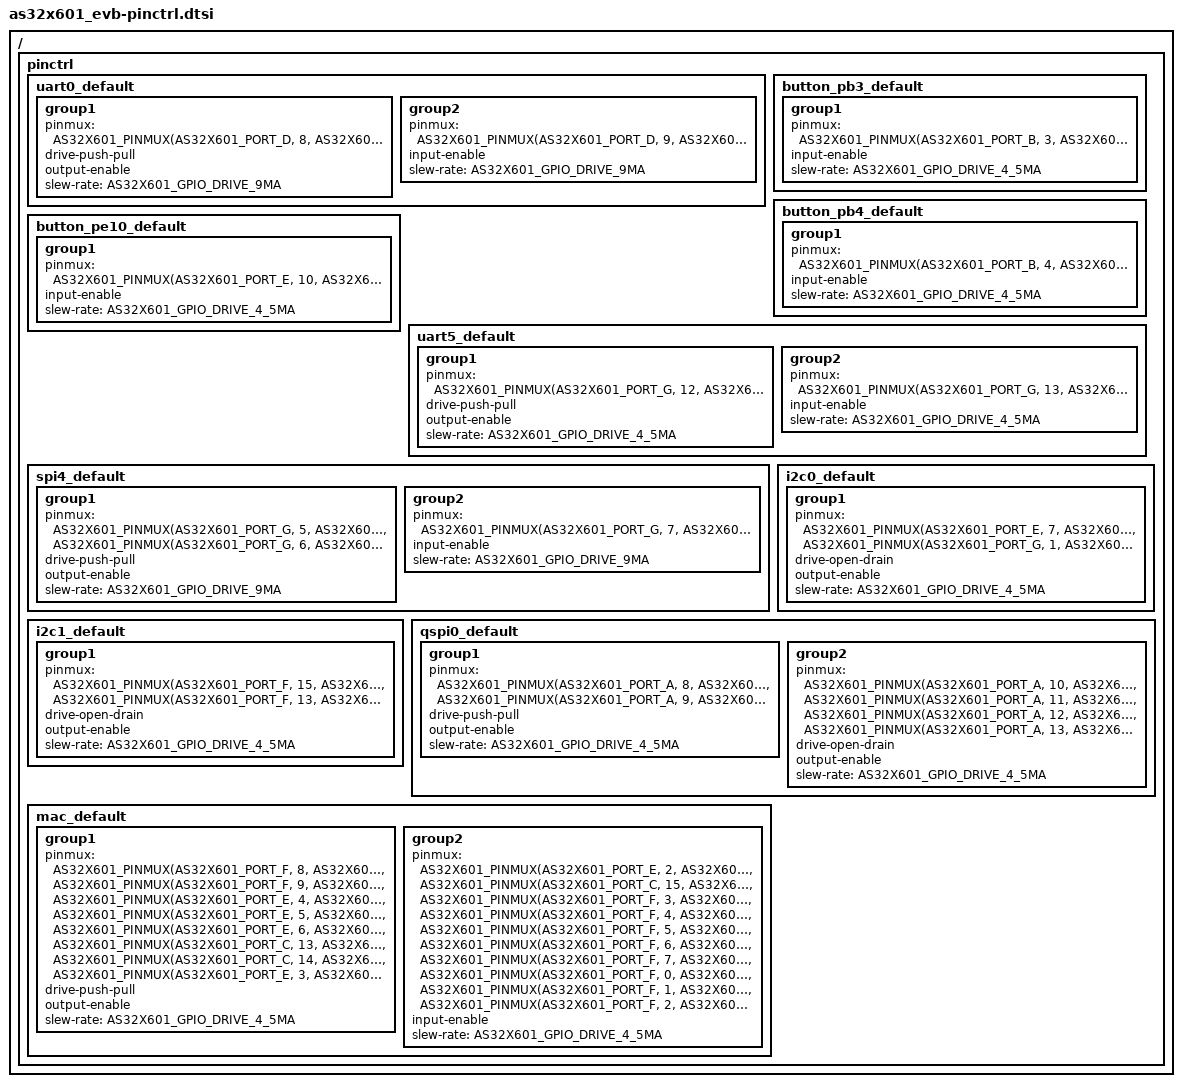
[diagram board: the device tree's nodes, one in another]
/* SPDX-License-Identifier: Apache-2.0 */

#include <zephyr/dt-bindings/pinctrl/ansilic-as32x601-pinctrl.h>

/ {
	pinctrl {
		uart0_default: uart0_default {
			group1 {
				pinmux = <AS32X601_PINMUX(AS32X601_PORT_D, 8, AS32X601_GPIO_AF_USART0)>;
				drive-push-pull;
				output-enable;
				slew-rate = <AS32X601_GPIO_DRIVE_9MA>;
			};
			group2 {
				pinmux = <AS32X601_PINMUX(AS32X601_PORT_D, 9, AS32X601_GPIO_AF_USART0)>;
				input-enable;
				slew-rate = <AS32X601_GPIO_DRIVE_9MA>;
			};
		};

		button_pb3_default: button_pb3_default {
			group1 {
				pinmux = <AS32X601_PINMUX(AS32X601_PORT_B, 3, AS32X601_GPIO_AF_PIN_X)>;
				input-enable;
				slew-rate = <AS32X601_GPIO_DRIVE_4_5MA>;
			};
		};

		button_pb4_default: button_pb4_default {
			group1 {
				pinmux = <AS32X601_PINMUX(AS32X601_PORT_B, 4, AS32X601_GPIO_AF_PIN_X)>;
				input-enable;
				slew-rate = <AS32X601_GPIO_DRIVE_4_5MA>;
			};
		};

		button_pe10_default: button_pe10_default {
			group1 {
				pinmux = <AS32X601_PINMUX(AS32X601_PORT_E, 10, AS32X601_GPIO_AF_PIN_X)>;
				input-enable;
				slew-rate = <AS32X601_GPIO_DRIVE_4_5MA>;
			};
		};

		uart5_default: uart5_default {
			group1 {
				pinmux = <AS32X601_PINMUX(AS32X601_PORT_G, 12, AS32X601_GPIO_AF_USART5)>;
				drive-push-pull;
				output-enable;
				slew-rate = <AS32X601_GPIO_DRIVE_4_5MA>;
			};
			group2 {
				pinmux = <AS32X601_PINMUX(AS32X601_PORT_G, 13, AS32X601_GPIO_AF_USART5)>;
				input-enable;
				slew-rate = <AS32X601_GPIO_DRIVE_4_5MA>;
			};
		};

		spi4_default: spi4_default {
			group1 {
				pinmux = <AS32X601_PINMUX(AS32X601_PORT_G, 5, AS32X601_GPIO_AF_SPI4)>,
				         <AS32X601_PINMUX(AS32X601_PORT_G, 6, AS32X601_GPIO_AF_SPI4)>;
				drive-push-pull;
				output-enable;
				slew-rate = <AS32X601_GPIO_DRIVE_9MA>;
			};
			group2 {
				pinmux = <AS32X601_PINMUX(AS32X601_PORT_G, 7, AS32X601_GPIO_AF_SPI4)>;
				input-enable;
				slew-rate = <AS32X601_GPIO_DRIVE_9MA>;
			};
		};

		i2c0_default: i2c0_default {
			group1 {
				pinmux = <AS32X601_PINMUX(AS32X601_PORT_E, 7, AS32X601_GPIO_AF_IIC0_M1)>,
				         <AS32X601_PINMUX(AS32X601_PORT_G, 1, AS32X601_GPIO_AF_IIC0_M1)>;
				drive-open-drain;
				output-enable;
				slew-rate = <AS32X601_GPIO_DRIVE_4_5MA>;
			};
		};

		i2c1_default: i2c1_default {
			group1 {
				pinmux = <AS32X601_PINMUX(AS32X601_PORT_F, 15, AS32X601_GPIO_AF_IIC1)>,
				         <AS32X601_PINMUX(AS32X601_PORT_F, 13, AS32X601_GPIO_AF_IIC1)>;
				drive-open-drain;
				output-enable;
				slew-rate = <AS32X601_GPIO_DRIVE_4_5MA>;
			};
		};

		qspi0_default: qspi0_default {
			group1 {
				pinmux = <AS32X601_PINMUX(AS32X601_PORT_A, 8,  AS32X601_GPIO_AF_QSPI)>,
					 <AS32X601_PINMUX(AS32X601_PORT_A, 9,  AS32X601_GPIO_AF_QSPI)>;
				drive-push-pull;
				output-enable;
				slew-rate = <AS32X601_GPIO_DRIVE_4_5MA>;
			};
			group2 {
				pinmux = <AS32X601_PINMUX(AS32X601_PORT_A, 10, AS32X601_GPIO_AF_QSPI)>,
					 <AS32X601_PINMUX(AS32X601_PORT_A, 11, AS32X601_GPIO_AF_QSPI)>,
					 <AS32X601_PINMUX(AS32X601_PORT_A, 12, AS32X601_GPIO_AF_QSPI)>,
					 <AS32X601_PINMUX(AS32X601_PORT_A, 13, AS32X601_GPIO_AF_QSPI)>;
				drive-open-drain;
				output-enable;
				slew-rate = <AS32X601_GPIO_DRIVE_4_5MA>;
			};
		};

		mac_default: mac_default {
			/* 输出引脚：MDC, MDIO, TXEN, TXD0-3, TXER */
			group1 {
				pinmux = <AS32X601_PINMUX(AS32X601_PORT_F, 8,  AS32X601_GPIO_AF_MAC)>,
				         <AS32X601_PINMUX(AS32X601_PORT_F, 9,  AS32X601_GPIO_AF_MAC)>,
				         <AS32X601_PINMUX(AS32X601_PORT_E, 4,  AS32X601_GPIO_AF_MAC)>,
				         <AS32X601_PINMUX(AS32X601_PORT_E, 5,  AS32X601_GPIO_AF_MAC)>,
				         <AS32X601_PINMUX(AS32X601_PORT_E, 6,  AS32X601_GPIO_AF_MAC)>,
				         <AS32X601_PINMUX(AS32X601_PORT_C, 13, AS32X601_GPIO_AF_MAC)>,
				         <AS32X601_PINMUX(AS32X601_PORT_C, 14, AS32X601_GPIO_AF_MAC)>,
				         <AS32X601_PINMUX(AS32X601_PORT_E, 3,  AS32X601_GPIO_AF_MAC)>;
				drive-push-pull;
				output-enable;
				slew-rate = <AS32X601_GPIO_DRIVE_4_5MA>;
			};
			/* 输入引脚：TXCLK, RXCLK, RXDV, RXD0-3, RXCOL, RXCRS, RXER */
			group2 {
				pinmux = <AS32X601_PINMUX(AS32X601_PORT_E, 2,  AS32X601_GPIO_AF_MAC)>,
				         <AS32X601_PINMUX(AS32X601_PORT_C, 15, AS32X601_GPIO_AF_MAC)>,
				         <AS32X601_PINMUX(AS32X601_PORT_F, 3,  AS32X601_GPIO_AF_MAC)>,
				         <AS32X601_PINMUX(AS32X601_PORT_F, 4,  AS32X601_GPIO_AF_MAC)>,
				         <AS32X601_PINMUX(AS32X601_PORT_F, 5,  AS32X601_GPIO_AF_MAC)>,
				         <AS32X601_PINMUX(AS32X601_PORT_F, 6,  AS32X601_GPIO_AF_MAC)>,
				         <AS32X601_PINMUX(AS32X601_PORT_F, 7,  AS32X601_GPIO_AF_MAC)>,
				         <AS32X601_PINMUX(AS32X601_PORT_F, 0,  AS32X601_GPIO_AF_MAC)>,
				         <AS32X601_PINMUX(AS32X601_PORT_F, 1,  AS32X601_GPIO_AF_MAC)>,
				         <AS32X601_PINMUX(AS32X601_PORT_F, 2,  AS32X601_GPIO_AF_MAC)>;
				input-enable;
				slew-rate = <AS32X601_GPIO_DRIVE_4_5MA>;
			};
		};
	};
};
